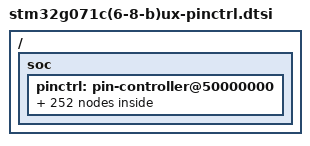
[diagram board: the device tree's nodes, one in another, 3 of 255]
/*
 * NOTE: Autogenerated file using genpinctrl.py
 *
 * SPDX-License-Identifier: Apache-2.0
 */

#include <zephyr/dt-bindings/pinctrl/stm32-pinctrl.h>

/ {
	soc {
		pinctrl: pin-controller@50000000 {

			/* ADC_IN / ADC_INN / ADC_INP */

			/omit-if-no-ref/ adc1_in0_pa0: adc1_in0_pa0 {
				pinmux = <STM32_PINMUX('A', 0, ANALOG)>;
			};

			/omit-if-no-ref/ adc1_in1_pa1: adc1_in1_pa1 {
				pinmux = <STM32_PINMUX('A', 1, ANALOG)>;
			};

			/omit-if-no-ref/ adc1_in2_pa2: adc1_in2_pa2 {
				pinmux = <STM32_PINMUX('A', 2, ANALOG)>;
			};

			/omit-if-no-ref/ adc1_in3_pa3: adc1_in3_pa3 {
				pinmux = <STM32_PINMUX('A', 3, ANALOG)>;
			};

			/omit-if-no-ref/ adc1_in4_pa4: adc1_in4_pa4 {
				pinmux = <STM32_PINMUX('A', 4, ANALOG)>;
			};

			/omit-if-no-ref/ adc1_in5_pa5: adc1_in5_pa5 {
				pinmux = <STM32_PINMUX('A', 5, ANALOG)>;
			};

			/omit-if-no-ref/ adc1_in6_pa6: adc1_in6_pa6 {
				pinmux = <STM32_PINMUX('A', 6, ANALOG)>;
			};

			/omit-if-no-ref/ adc1_in7_pa7: adc1_in7_pa7 {
				pinmux = <STM32_PINMUX('A', 7, ANALOG)>;
			};

			/omit-if-no-ref/ adc1_in8_pb0: adc1_in8_pb0 {
				pinmux = <STM32_PINMUX('B', 0, ANALOG)>;
			};

			/omit-if-no-ref/ adc1_in9_pb1: adc1_in9_pb1 {
				pinmux = <STM32_PINMUX('B', 1, ANALOG)>;
			};

			/omit-if-no-ref/ adc1_in10_pb2: adc1_in10_pb2 {
				pinmux = <STM32_PINMUX('B', 2, ANALOG)>;
			};

			/omit-if-no-ref/ adc1_in11_pb10: adc1_in11_pb10 {
				pinmux = <STM32_PINMUX('B', 10, ANALOG)>;
			};

			/omit-if-no-ref/ adc1_in15_pb11: adc1_in15_pb11 {
				pinmux = <STM32_PINMUX('B', 11, ANALOG)>;
			};

			/omit-if-no-ref/ adc1_in16_pb12: adc1_in16_pb12 {
				pinmux = <STM32_PINMUX('B', 12, ANALOG)>;
			};

			/* Analog */

			/omit-if-no-ref/ analog_pa0: analog_pa0 {
				pinmux = <STM32_PINMUX('A', 0, ANALOG)>;
			};

			/omit-if-no-ref/ analog_pa1: analog_pa1 {
				pinmux = <STM32_PINMUX('A', 1, ANALOG)>;
			};

			/omit-if-no-ref/ analog_pa2: analog_pa2 {
				pinmux = <STM32_PINMUX('A', 2, ANALOG)>;
			};

			/omit-if-no-ref/ analog_pa3: analog_pa3 {
				pinmux = <STM32_PINMUX('A', 3, ANALOG)>;
			};

			/omit-if-no-ref/ analog_pa4: analog_pa4 {
				pinmux = <STM32_PINMUX('A', 4, ANALOG)>;
			};

			/omit-if-no-ref/ analog_pa5: analog_pa5 {
				pinmux = <STM32_PINMUX('A', 5, ANALOG)>;
			};

			/omit-if-no-ref/ analog_pa6: analog_pa6 {
				pinmux = <STM32_PINMUX('A', 6, ANALOG)>;
			};

			/omit-if-no-ref/ analog_pa7: analog_pa7 {
				pinmux = <STM32_PINMUX('A', 7, ANALOG)>;
			};

			/omit-if-no-ref/ analog_pa8: analog_pa8 {
				pinmux = <STM32_PINMUX('A', 8, ANALOG)>;
			};

			/omit-if-no-ref/ analog_pa9: analog_pa9 {
				pinmux = <STM32_PINMUX('A', 9, ANALOG)>;
			};

			/omit-if-no-ref/ analog_pa10: analog_pa10 {
				pinmux = <STM32_PINMUX('A', 10, ANALOG)>;
			};

			/omit-if-no-ref/ analog_pa11: analog_pa11 {
				pinmux = <STM32_PINMUX('A', 11, ANALOG)>;
			};

			/omit-if-no-ref/ analog_pa12: analog_pa12 {
				pinmux = <STM32_PINMUX('A', 12, ANALOG)>;
			};

			/omit-if-no-ref/ analog_pa13: analog_pa13 {
				pinmux = <STM32_PINMUX('A', 13, ANALOG)>;
			};

			/omit-if-no-ref/ analog_pa14: analog_pa14 {
				pinmux = <STM32_PINMUX('A', 14, ANALOG)>;
			};

			/omit-if-no-ref/ analog_pa15: analog_pa15 {
				pinmux = <STM32_PINMUX('A', 15, ANALOG)>;
			};

			/omit-if-no-ref/ analog_pb0: analog_pb0 {
				pinmux = <STM32_PINMUX('B', 0, ANALOG)>;
			};

			/omit-if-no-ref/ analog_pb1: analog_pb1 {
				pinmux = <STM32_PINMUX('B', 1, ANALOG)>;
			};

			/omit-if-no-ref/ analog_pb2: analog_pb2 {
				pinmux = <STM32_PINMUX('B', 2, ANALOG)>;
			};

			/omit-if-no-ref/ analog_pb3: analog_pb3 {
				pinmux = <STM32_PINMUX('B', 3, ANALOG)>;
			};

			/omit-if-no-ref/ analog_pb4: analog_pb4 {
				pinmux = <STM32_PINMUX('B', 4, ANALOG)>;
			};

			/omit-if-no-ref/ analog_pb5: analog_pb5 {
				pinmux = <STM32_PINMUX('B', 5, ANALOG)>;
			};

			/omit-if-no-ref/ analog_pb6: analog_pb6 {
				pinmux = <STM32_PINMUX('B', 6, ANALOG)>;
			};

			/omit-if-no-ref/ analog_pb7: analog_pb7 {
				pinmux = <STM32_PINMUX('B', 7, ANALOG)>;
			};

			/omit-if-no-ref/ analog_pb8: analog_pb8 {
				pinmux = <STM32_PINMUX('B', 8, ANALOG)>;
			};

			/omit-if-no-ref/ analog_pb9: analog_pb9 {
				pinmux = <STM32_PINMUX('B', 9, ANALOG)>;
			};

			/omit-if-no-ref/ analog_pb10: analog_pb10 {
				pinmux = <STM32_PINMUX('B', 10, ANALOG)>;
			};

			/omit-if-no-ref/ analog_pb11: analog_pb11 {
				pinmux = <STM32_PINMUX('B', 11, ANALOG)>;
			};

			/omit-if-no-ref/ analog_pb12: analog_pb12 {
				pinmux = <STM32_PINMUX('B', 12, ANALOG)>;
			};

			/omit-if-no-ref/ analog_pb13: analog_pb13 {
				pinmux = <STM32_PINMUX('B', 13, ANALOG)>;
			};

			/omit-if-no-ref/ analog_pb14: analog_pb14 {
				pinmux = <STM32_PINMUX('B', 14, ANALOG)>;
			};

			/omit-if-no-ref/ analog_pb15: analog_pb15 {
				pinmux = <STM32_PINMUX('B', 15, ANALOG)>;
			};

			/omit-if-no-ref/ analog_pc6: analog_pc6 {
				pinmux = <STM32_PINMUX('C', 6, ANALOG)>;
			};

			/omit-if-no-ref/ analog_pc7: analog_pc7 {
				pinmux = <STM32_PINMUX('C', 7, ANALOG)>;
			};

			/omit-if-no-ref/ analog_pc13: analog_pc13 {
				pinmux = <STM32_PINMUX('C', 13, ANALOG)>;
			};

			/omit-if-no-ref/ analog_pc14: analog_pc14 {
				pinmux = <STM32_PINMUX('C', 14, ANALOG)>;
			};

			/omit-if-no-ref/ analog_pc15: analog_pc15 {
				pinmux = <STM32_PINMUX('C', 15, ANALOG)>;
			};

			/omit-if-no-ref/ analog_pd0: analog_pd0 {
				pinmux = <STM32_PINMUX('D', 0, ANALOG)>;
			};

			/omit-if-no-ref/ analog_pd1: analog_pd1 {
				pinmux = <STM32_PINMUX('D', 1, ANALOG)>;
			};

			/omit-if-no-ref/ analog_pd2: analog_pd2 {
				pinmux = <STM32_PINMUX('D', 2, ANALOG)>;
			};

			/omit-if-no-ref/ analog_pd3: analog_pd3 {
				pinmux = <STM32_PINMUX('D', 3, ANALOG)>;
			};

			/omit-if-no-ref/ analog_pf0: analog_pf0 {
				pinmux = <STM32_PINMUX('F', 0, ANALOG)>;
			};

			/omit-if-no-ref/ analog_pf1: analog_pf1 {
				pinmux = <STM32_PINMUX('F', 1, ANALOG)>;
			};

			/omit-if-no-ref/ analog_pf2: analog_pf2 {
				pinmux = <STM32_PINMUX('F', 2, ANALOG)>;
			};

			/* COMP_IN */

			/omit-if-no-ref/ comp1_inm_pa0: comp1_inm_pa0 {
				pinmux = <STM32_PINMUX('A', 0, ANALOG)>;
			};

			/omit-if-no-ref/ comp1_inp_pa1: comp1_inp_pa1 {
				pinmux = <STM32_PINMUX('A', 1, ANALOG)>;
			};

			/omit-if-no-ref/ comp1_inm_pb1: comp1_inm_pb1 {
				pinmux = <STM32_PINMUX('B', 1, ANALOG)>;
			};

			/omit-if-no-ref/ comp1_inp_pb2: comp1_inp_pb2 {
				pinmux = <STM32_PINMUX('B', 2, ANALOG)>;
			};

			/omit-if-no-ref/ comp2_inm_pa2: comp2_inm_pa2 {
				pinmux = <STM32_PINMUX('A', 2, ANALOG)>;
			};

			/omit-if-no-ref/ comp2_inp_pa3: comp2_inp_pa3 {
				pinmux = <STM32_PINMUX('A', 3, ANALOG)>;
			};

			/omit-if-no-ref/ comp2_inm_pb3: comp2_inm_pb3 {
				pinmux = <STM32_PINMUX('B', 3, ANALOG)>;
			};

			/omit-if-no-ref/ comp2_inp_pb4: comp2_inp_pb4 {
				pinmux = <STM32_PINMUX('B', 4, ANALOG)>;
			};

			/omit-if-no-ref/ comp2_inp_pb6: comp2_inp_pb6 {
				pinmux = <STM32_PINMUX('B', 6, ANALOG)>;
			};

			/omit-if-no-ref/ comp2_inm_pb7: comp2_inm_pb7 {
				pinmux = <STM32_PINMUX('B', 7, ANALOG)>;
			};

			/* COMP_OUT */

			/omit-if-no-ref/ comp1_out_pa0: comp1_out_pa0 {
				pinmux = <STM32_PINMUX('A', 0, AF7)>;
			};

			/omit-if-no-ref/ comp1_out_pa6: comp1_out_pa6 {
				pinmux = <STM32_PINMUX('A', 6, AF7)>;
			};

			/omit-if-no-ref/ comp1_out_pa11: comp1_out_pa11 {
				pinmux = <STM32_PINMUX('A', 11, AF7)>;
			};

			/omit-if-no-ref/ comp1_out_pb0: comp1_out_pb0 {
				pinmux = <STM32_PINMUX('B', 0, AF7)>;
			};

			/omit-if-no-ref/ comp1_out_pb10: comp1_out_pb10 {
				pinmux = <STM32_PINMUX('B', 10, AF7)>;
			};

			/omit-if-no-ref/ comp2_out_pa2: comp2_out_pa2 {
				pinmux = <STM32_PINMUX('A', 2, AF7)>;
			};

			/omit-if-no-ref/ comp2_out_pa7: comp2_out_pa7 {
				pinmux = <STM32_PINMUX('A', 7, AF7)>;
			};

			/omit-if-no-ref/ comp2_out_pa12: comp2_out_pa12 {
				pinmux = <STM32_PINMUX('A', 12, AF7)>;
			};

			/omit-if-no-ref/ comp2_out_pb5: comp2_out_pb5 {
				pinmux = <STM32_PINMUX('B', 5, AF7)>;
			};

			/omit-if-no-ref/ comp2_out_pb11: comp2_out_pb11 {
				pinmux = <STM32_PINMUX('B', 11, AF7)>;
			};

			/* DAC_OUT */

			/omit-if-no-ref/ dac1_out1_pa4: dac1_out1_pa4 {
				pinmux = <STM32_PINMUX('A', 4, ANALOG)>;
			};

			/omit-if-no-ref/ dac1_out2_pa5: dac1_out2_pa5 {
				pinmux = <STM32_PINMUX('A', 5, ANALOG)>;
			};

			/* I2C_SCL */

			/omit-if-no-ref/ i2c1_scl_pa9: i2c1_scl_pa9 {
				pinmux = <STM32_PINMUX('A', 9, AF6)>;
				bias-pull-up;
				drive-open-drain;
			};

			/omit-if-no-ref/ i2c1_scl_pb6: i2c1_scl_pb6 {
				pinmux = <STM32_PINMUX('B', 6, AF6)>;
				bias-pull-up;
				drive-open-drain;
			};

			/omit-if-no-ref/ i2c1_scl_pb8: i2c1_scl_pb8 {
				pinmux = <STM32_PINMUX('B', 8, AF6)>;
				bias-pull-up;
				drive-open-drain;
			};

			/omit-if-no-ref/ i2c2_scl_pa11: i2c2_scl_pa11 {
				pinmux = <STM32_PINMUX('A', 11, AF6)>;
				bias-pull-up;
				drive-open-drain;
			};

			/omit-if-no-ref/ i2c2_scl_pb10: i2c2_scl_pb10 {
				pinmux = <STM32_PINMUX('B', 10, AF6)>;
				bias-pull-up;
				drive-open-drain;
			};

			/omit-if-no-ref/ i2c2_scl_pb13: i2c2_scl_pb13 {
				pinmux = <STM32_PINMUX('B', 13, AF6)>;
				bias-pull-up;
				drive-open-drain;
			};

			/* I2C_SDA */

			/omit-if-no-ref/ i2c1_sda_pa10: i2c1_sda_pa10 {
				pinmux = <STM32_PINMUX('A', 10, AF6)>;
				bias-pull-up;
				drive-open-drain;
			};

			/omit-if-no-ref/ i2c1_sda_pb7: i2c1_sda_pb7 {
				pinmux = <STM32_PINMUX('B', 7, AF6)>;
				bias-pull-up;
				drive-open-drain;
			};

			/omit-if-no-ref/ i2c1_sda_pb9: i2c1_sda_pb9 {
				pinmux = <STM32_PINMUX('B', 9, AF6)>;
				bias-pull-up;
				drive-open-drain;
			};

			/omit-if-no-ref/ i2c2_sda_pa12: i2c2_sda_pa12 {
				pinmux = <STM32_PINMUX('A', 12, AF6)>;
				bias-pull-up;
				drive-open-drain;
			};

			/omit-if-no-ref/ i2c2_sda_pb11: i2c2_sda_pb11 {
				pinmux = <STM32_PINMUX('B', 11, AF6)>;
				bias-pull-up;
				drive-open-drain;
			};

			/omit-if-no-ref/ i2c2_sda_pb14: i2c2_sda_pb14 {
				pinmux = <STM32_PINMUX('B', 14, AF6)>;
				bias-pull-up;
				drive-open-drain;
			};

			/* I2C_SMBA */

			/omit-if-no-ref/ i2c1_smba_pa1: i2c1_smba_pa1 {
				pinmux = <STM32_PINMUX('A', 1, AF6)>;
				bias-pull-up;
			};

			/omit-if-no-ref/ i2c1_smba_pb5: i2c1_smba_pb5 {
				pinmux = <STM32_PINMUX('B', 5, AF6)>;
				bias-pull-up;
			};

			/* I2S_CK */

			/omit-if-no-ref/ i2s1_ck_pa1: i2s1_ck_pa1 {
				pinmux = <STM32_PINMUX('A', 1, AF0)>;
				slew-rate = "very-high-speed";
			};

			/omit-if-no-ref/ i2s1_ck_pa5: i2s1_ck_pa5 {
				pinmux = <STM32_PINMUX('A', 5, AF0)>;
				slew-rate = "very-high-speed";
			};

			/omit-if-no-ref/ i2s1_ck_pb3: i2s1_ck_pb3 {
				pinmux = <STM32_PINMUX('B', 3, AF0)>;
				slew-rate = "very-high-speed";
			};

			/* I2S_MCK */

			/omit-if-no-ref/ i2s1_mck_pa6: i2s1_mck_pa6 {
				pinmux = <STM32_PINMUX('A', 6, AF0)>;
				slew-rate = "very-high-speed";
			};

			/omit-if-no-ref/ i2s1_mck_pa11: i2s1_mck_pa11 {
				pinmux = <STM32_PINMUX('A', 11, AF0)>;
				slew-rate = "very-high-speed";
			};

			/omit-if-no-ref/ i2s1_mck_pb4: i2s1_mck_pb4 {
				pinmux = <STM32_PINMUX('B', 4, AF0)>;
				slew-rate = "very-high-speed";
			};

			/* I2S_SD */

			/omit-if-no-ref/ i2s1_sd_pa2: i2s1_sd_pa2 {
				pinmux = <STM32_PINMUX('A', 2, AF0)>;
			};

			/omit-if-no-ref/ i2s1_sd_pa7: i2s1_sd_pa7 {
				pinmux = <STM32_PINMUX('A', 7, AF0)>;
			};

			/omit-if-no-ref/ i2s1_sd_pa12: i2s1_sd_pa12 {
				pinmux = <STM32_PINMUX('A', 12, AF0)>;
			};

			/omit-if-no-ref/ i2s1_sd_pb5: i2s1_sd_pb5 {
				pinmux = <STM32_PINMUX('B', 5, AF0)>;
			};

			/* I2S_WS */

			/omit-if-no-ref/ i2s1_ws_pa4: i2s1_ws_pa4 {
				pinmux = <STM32_PINMUX('A', 4, AF0)>;
			};

			/omit-if-no-ref/ i2s1_ws_pa15: i2s1_ws_pa15 {
				pinmux = <STM32_PINMUX('A', 15, AF0)>;
			};

			/omit-if-no-ref/ i2s1_ws_pb0: i2s1_ws_pb0 {
				pinmux = <STM32_PINMUX('B', 0, AF0)>;
			};

			/* JTAG PORT */

			/omit-if-no-ref/ sys_swdio_pa13: sys_swdio_pa13 {
				pinmux = <STM32_PINMUX('A', 13, AF0)>;
			};

			/omit-if-no-ref/ sys_swclk_pa14: sys_swclk_pa14 {
				pinmux = <STM32_PINMUX('A', 14, AF0)>;
			};

			/* RCC_MCO */

			/omit-if-no-ref/ rcc_mco_pa8: rcc_mco_pa8 {
				pinmux = <STM32_PINMUX('A', 8, AF0)>;
				slew-rate = "very-high-speed";
			};

			/omit-if-no-ref/ rcc_mco_pa9: rcc_mco_pa9 {
				pinmux = <STM32_PINMUX('A', 9, AF0)>;
				slew-rate = "very-high-speed";
			};

			/omit-if-no-ref/ rcc_mco_pf2: rcc_mco_pf2 {
				pinmux = <STM32_PINMUX('F', 2, AF0)>;
				slew-rate = "very-high-speed";
			};

			/* SPI_MISO */

			/omit-if-no-ref/ spi1_miso_pa6: spi1_miso_pa6 {
				pinmux = <STM32_PINMUX('A', 6, AF0)>;
				bias-pull-down;
			};

			/omit-if-no-ref/ spi1_miso_pa11: spi1_miso_pa11 {
				pinmux = <STM32_PINMUX('A', 11, AF0)>;
				bias-pull-down;
			};

			/omit-if-no-ref/ spi1_miso_pb4: spi1_miso_pb4 {
				pinmux = <STM32_PINMUX('B', 4, AF0)>;
				bias-pull-down;
			};

			/omit-if-no-ref/ spi2_miso_pa3: spi2_miso_pa3 {
				pinmux = <STM32_PINMUX('A', 3, AF0)>;
				bias-pull-down;
			};

			/omit-if-no-ref/ spi2_miso_pa9: spi2_miso_pa9 {
				pinmux = <STM32_PINMUX('A', 9, AF4)>;
				bias-pull-down;
			};

			/omit-if-no-ref/ spi2_miso_pb2: spi2_miso_pb2 {
				pinmux = <STM32_PINMUX('B', 2, AF1)>;
				bias-pull-down;
			};

			/omit-if-no-ref/ spi2_miso_pb6: spi2_miso_pb6 {
				pinmux = <STM32_PINMUX('B', 6, AF4)>;
				bias-pull-down;
			};

			/omit-if-no-ref/ spi2_miso_pb14: spi2_miso_pb14 {
				pinmux = <STM32_PINMUX('B', 14, AF0)>;
				bias-pull-down;
			};

			/omit-if-no-ref/ spi2_miso_pd3: spi2_miso_pd3 {
				pinmux = <STM32_PINMUX('D', 3, AF1)>;
				bias-pull-down;
			};

			/* SPI_MOSI */

			/omit-if-no-ref/ spi1_mosi_pa2: spi1_mosi_pa2 {
				pinmux = <STM32_PINMUX('A', 2, AF0)>;
				bias-pull-down;
			};

			/omit-if-no-ref/ spi1_mosi_pa7: spi1_mosi_pa7 {
				pinmux = <STM32_PINMUX('A', 7, AF0)>;
				bias-pull-down;
			};

			/omit-if-no-ref/ spi1_mosi_pa12: spi1_mosi_pa12 {
				pinmux = <STM32_PINMUX('A', 12, AF0)>;
				bias-pull-down;
			};

			/omit-if-no-ref/ spi1_mosi_pb5: spi1_mosi_pb5 {
				pinmux = <STM32_PINMUX('B', 5, AF0)>;
				bias-pull-down;
			};

			/omit-if-no-ref/ spi2_mosi_pa4: spi2_mosi_pa4 {
				pinmux = <STM32_PINMUX('A', 4, AF1)>;
				bias-pull-down;
			};

			/omit-if-no-ref/ spi2_mosi_pa10: spi2_mosi_pa10 {
				pinmux = <STM32_PINMUX('A', 10, AF0)>;
				bias-pull-down;
			};

			/omit-if-no-ref/ spi2_mosi_pb7: spi2_mosi_pb7 {
				pinmux = <STM32_PINMUX('B', 7, AF1)>;
				bias-pull-down;
			};

			/omit-if-no-ref/ spi2_mosi_pb11: spi2_mosi_pb11 {
				pinmux = <STM32_PINMUX('B', 11, AF0)>;
				bias-pull-down;
			};

			/omit-if-no-ref/ spi2_mosi_pb15: spi2_mosi_pb15 {
				pinmux = <STM32_PINMUX('B', 15, AF0)>;
				bias-pull-down;
			};

			/* SPI_NSS */

			/omit-if-no-ref/ spi1_nss_pa4: spi1_nss_pa4 {
				pinmux = <STM32_PINMUX('A', 4, AF0)>;
				bias-pull-up;
			};

			/omit-if-no-ref/ spi1_nss_pa15: spi1_nss_pa15 {
				pinmux = <STM32_PINMUX('A', 15, AF0)>;
				bias-pull-up;
			};

			/omit-if-no-ref/ spi1_nss_pb0: spi1_nss_pb0 {
				pinmux = <STM32_PINMUX('B', 0, AF0)>;
				bias-pull-up;
			};

			/omit-if-no-ref/ spi2_nss_pa8: spi2_nss_pa8 {
				pinmux = <STM32_PINMUX('A', 8, AF1)>;
				bias-pull-up;
			};

			/omit-if-no-ref/ spi2_nss_pb9: spi2_nss_pb9 {
				pinmux = <STM32_PINMUX('B', 9, AF5)>;
				bias-pull-up;
			};

			/omit-if-no-ref/ spi2_nss_pb12: spi2_nss_pb12 {
				pinmux = <STM32_PINMUX('B', 12, AF0)>;
				bias-pull-up;
			};

			/omit-if-no-ref/ spi2_nss_pd0: spi2_nss_pd0 {
				pinmux = <STM32_PINMUX('D', 0, AF1)>;
				bias-pull-up;
			};

			/* SPI_SCK */

			/omit-if-no-ref/ spi1_sck_pa1: spi1_sck_pa1 {
				pinmux = <STM32_PINMUX('A', 1, AF0)>;
				bias-pull-down;
				slew-rate = "very-high-speed";
			};

			/omit-if-no-ref/ spi1_sck_pa5: spi1_sck_pa5 {
				pinmux = <STM32_PINMUX('A', 5, AF0)>;
				bias-pull-down;
				slew-rate = "very-high-speed";
			};

			/omit-if-no-ref/ spi1_sck_pb3: spi1_sck_pb3 {
				pinmux = <STM32_PINMUX('B', 3, AF0)>;
				bias-pull-down;
				slew-rate = "very-high-speed";
			};

			/omit-if-no-ref/ spi2_sck_pa0: spi2_sck_pa0 {
				pinmux = <STM32_PINMUX('A', 0, AF0)>;
				bias-pull-down;
				slew-rate = "very-high-speed";
			};

			/omit-if-no-ref/ spi2_sck_pb8: spi2_sck_pb8 {
				pinmux = <STM32_PINMUX('B', 8, AF1)>;
				bias-pull-down;
				slew-rate = "very-high-speed";
			};

			/omit-if-no-ref/ spi2_sck_pb10: spi2_sck_pb10 {
				pinmux = <STM32_PINMUX('B', 10, AF5)>;
				bias-pull-down;
				slew-rate = "very-high-speed";
			};

			/omit-if-no-ref/ spi2_sck_pb13: spi2_sck_pb13 {
				pinmux = <STM32_PINMUX('B', 13, AF0)>;
				bias-pull-down;
				slew-rate = "very-high-speed";
			};

			/omit-if-no-ref/ spi2_sck_pd1: spi2_sck_pd1 {
				pinmux = <STM32_PINMUX('D', 1, AF1)>;
				bias-pull-down;
				slew-rate = "very-high-speed";
			};

			/* TIM_CH / TIM_CHN */

			/omit-if-no-ref/ tim1_ch1n_pa7: tim1_ch1n_pa7 {
				pinmux = <STM32_PINMUX('A', 7, AF2)>;
			};

			/omit-if-no-ref/ tim1_ch1_pa8: tim1_ch1_pa8 {
				pinmux = <STM32_PINMUX('A', 8, AF2)>;
			};

			/omit-if-no-ref/ tim1_ch2_pa9: tim1_ch2_pa9 {
				pinmux = <STM32_PINMUX('A', 9, AF2)>;
			};

			/omit-if-no-ref/ tim1_ch3_pa10: tim1_ch3_pa10 {
				pinmux = <STM32_PINMUX('A', 10, AF2)>;
			};

			/omit-if-no-ref/ tim1_ch4_pa11: tim1_ch4_pa11 {
				pinmux = <STM32_PINMUX('A', 11, AF2)>;
			};

			/omit-if-no-ref/ tim1_ch2n_pb0: tim1_ch2n_pb0 {
				pinmux = <STM32_PINMUX('B', 0, AF2)>;
			};

			/omit-if-no-ref/ tim1_ch3n_pb1: tim1_ch3n_pb1 {
				pinmux = <STM32_PINMUX('B', 1, AF2)>;
			};

			/omit-if-no-ref/ tim1_ch2_pb3: tim1_ch2_pb3 {
				pinmux = <STM32_PINMUX('B', 3, AF1)>;
			};

			/omit-if-no-ref/ tim1_ch3_pb6: tim1_ch3_pb6 {
				pinmux = <STM32_PINMUX('B', 6, AF1)>;
			};

			/omit-if-no-ref/ tim1_ch1n_pb13: tim1_ch1n_pb13 {
				pinmux = <STM32_PINMUX('B', 13, AF2)>;
			};

			/omit-if-no-ref/ tim1_ch2n_pb14: tim1_ch2n_pb14 {
				pinmux = <STM32_PINMUX('B', 14, AF2)>;
			};

			/omit-if-no-ref/ tim1_ch3n_pb15: tim1_ch3n_pb15 {
				pinmux = <STM32_PINMUX('B', 15, AF2)>;
			};

			/omit-if-no-ref/ tim1_ch1n_pd2: tim1_ch1n_pd2 {
				pinmux = <STM32_PINMUX('D', 2, AF2)>;
			};

			/omit-if-no-ref/ tim1_ch2n_pd3: tim1_ch2n_pd3 {
				pinmux = <STM32_PINMUX('D', 3, AF2)>;
			};

			/omit-if-no-ref/ tim2_ch1_pa0: tim2_ch1_pa0 {
				pinmux = <STM32_PINMUX('A', 0, AF2)>;
			};

			/omit-if-no-ref/ tim2_ch2_pa1: tim2_ch2_pa1 {
				pinmux = <STM32_PINMUX('A', 1, AF2)>;
			};

			/omit-if-no-ref/ tim2_ch3_pa2: tim2_ch3_pa2 {
				pinmux = <STM32_PINMUX('A', 2, AF2)>;
			};

			/omit-if-no-ref/ tim2_ch4_pa3: tim2_ch4_pa3 {
				pinmux = <STM32_PINMUX('A', 3, AF2)>;
			};

			/omit-if-no-ref/ tim2_ch1_pa5: tim2_ch1_pa5 {
				pinmux = <STM32_PINMUX('A', 5, AF2)>;
			};

			/omit-if-no-ref/ tim2_ch1_pa15: tim2_ch1_pa15 {
				pinmux = <STM32_PINMUX('A', 15, AF2)>;
			};

			/omit-if-no-ref/ tim2_ch2_pb3: tim2_ch2_pb3 {
				pinmux = <STM32_PINMUX('B', 3, AF2)>;
			};

			/omit-if-no-ref/ tim2_ch3_pb10: tim2_ch3_pb10 {
				pinmux = <STM32_PINMUX('B', 10, AF2)>;
			};

			/omit-if-no-ref/ tim2_ch4_pb11: tim2_ch4_pb11 {
				pinmux = <STM32_PINMUX('B', 11, AF2)>;
			};

			/omit-if-no-ref/ tim2_ch3_pc6: tim2_ch3_pc6 {
				pinmux = <STM32_PINMUX('C', 6, AF2)>;
			};

			/omit-if-no-ref/ tim2_ch4_pc7: tim2_ch4_pc7 {
				pinmux = <STM32_PINMUX('C', 7, AF2)>;
			};

			/omit-if-no-ref/ tim3_ch1_pa6: tim3_ch1_pa6 {
				pinmux = <STM32_PINMUX('A', 6, AF1)>;
			};

			/omit-if-no-ref/ tim3_ch2_pa7: tim3_ch2_pa7 {
				pinmux = <STM32_PINMUX('A', 7, AF1)>;
			};

			/omit-if-no-ref/ tim3_ch3_pb0: tim3_ch3_pb0 {
				pinmux = <STM32_PINMUX('B', 0, AF1)>;
			};

			/omit-if-no-ref/ tim3_ch4_pb1: tim3_ch4_pb1 {
				pinmux = <STM32_PINMUX('B', 1, AF1)>;
			};

			/omit-if-no-ref/ tim3_ch1_pb4: tim3_ch1_pb4 {
				pinmux = <STM32_PINMUX('B', 4, AF1)>;
			};

			/omit-if-no-ref/ tim3_ch2_pb5: tim3_ch2_pb5 {
				pinmux = <STM32_PINMUX('B', 5, AF1)>;
			};

			/omit-if-no-ref/ tim3_ch1_pc6: tim3_ch1_pc6 {
				pinmux = <STM32_PINMUX('C', 6, AF1)>;
			};

			/omit-if-no-ref/ tim3_ch2_pc7: tim3_ch2_pc7 {
				pinmux = <STM32_PINMUX('C', 7, AF1)>;
			};

			/omit-if-no-ref/ tim14_ch1_pa4: tim14_ch1_pa4 {
				pinmux = <STM32_PINMUX('A', 4, AF4)>;
			};

			/omit-if-no-ref/ tim14_ch1_pa7: tim14_ch1_pa7 {
				pinmux = <STM32_PINMUX('A', 7, AF4)>;
			};

			/omit-if-no-ref/ tim14_ch1_pb1: tim14_ch1_pb1 {
				pinmux = <STM32_PINMUX('B', 1, AF0)>;
			};

			/omit-if-no-ref/ tim14_ch1_pf0: tim14_ch1_pf0 {
				pinmux = <STM32_PINMUX('F', 0, AF2)>;
			};

			/omit-if-no-ref/ tim15_ch1n_pa1: tim15_ch1n_pa1 {
				pinmux = <STM32_PINMUX('A', 1, AF5)>;
			};

			/omit-if-no-ref/ tim15_ch1_pa2: tim15_ch1_pa2 {
				pinmux = <STM32_PINMUX('A', 2, AF5)>;
			};

			/omit-if-no-ref/ tim15_ch2_pa3: tim15_ch2_pa3 {
				pinmux = <STM32_PINMUX('A', 3, AF5)>;
			};

			/omit-if-no-ref/ tim15_ch1n_pb13: tim15_ch1n_pb13 {
				pinmux = <STM32_PINMUX('B', 13, AF5)>;
			};

			/omit-if-no-ref/ tim15_ch1_pb14: tim15_ch1_pb14 {
				pinmux = <STM32_PINMUX('B', 14, AF5)>;
			};

			/omit-if-no-ref/ tim15_ch1n_pb15: tim15_ch1n_pb15 {
				pinmux = <STM32_PINMUX('B', 15, AF4)>;
			};

			/omit-if-no-ref/ tim15_ch2_pb15: tim15_ch2_pb15 {
				pinmux = <STM32_PINMUX('B', 15, AF5)>;
			};

			/omit-if-no-ref/ tim15_ch1n_pf1: tim15_ch1n_pf1 {
				pinmux = <STM32_PINMUX('F', 1, AF2)>;
			};

			/omit-if-no-ref/ tim16_ch1_pa6: tim16_ch1_pa6 {
				pinmux = <STM32_PINMUX('A', 6, AF5)>;
			};

			/omit-if-no-ref/ tim16_ch1n_pb6: tim16_ch1n_pb6 {
				pinmux = <STM32_PINMUX('B', 6, AF2)>;
			};

			/omit-if-no-ref/ tim16_ch1_pb8: tim16_ch1_pb8 {
				pinmux = <STM32_PINMUX('B', 8, AF2)>;
			};

			/omit-if-no-ref/ tim16_ch1_pd0: tim16_ch1_pd0 {
				pinmux = <STM32_PINMUX('D', 0, AF2)>;
			};

			/omit-if-no-ref/ tim17_ch1_pa7: tim17_ch1_pa7 {
				pinmux = <STM32_PINMUX('A', 7, AF5)>;
			};

			/omit-if-no-ref/ tim17_ch1n_pb7: tim17_ch1n_pb7 {
				pinmux = <STM32_PINMUX('B', 7, AF2)>;
			};

			/omit-if-no-ref/ tim17_ch1_pb9: tim17_ch1_pb9 {
				pinmux = <STM32_PINMUX('B', 9, AF2)>;
			};

			/omit-if-no-ref/ tim17_ch1_pd1: tim17_ch1_pd1 {
				pinmux = <STM32_PINMUX('D', 1, AF2)>;
			};

			/* UART_CTS / USART_CTS / LPUART_CTS */

			/omit-if-no-ref/ lpuart1_cts_pa6: lpuart1_cts_pa6 {
				pinmux = <STM32_PINMUX('A', 6, AF6)>;
				bias-pull-up;
			};

			/omit-if-no-ref/ usart1_cts_pa11: usart1_cts_pa11 {
				pinmux = <STM32_PINMUX('A', 11, AF1)>;
				bias-pull-up;
			};

			/omit-if-no-ref/ usart1_cts_pb4: usart1_cts_pb4 {
				pinmux = <STM32_PINMUX('B', 4, AF4)>;
				bias-pull-up;
			};

			/omit-if-no-ref/ lpuart1_cts_pb13: lpuart1_cts_pb13 {
				pinmux = <STM32_PINMUX('B', 13, AF1)>;
				bias-pull-up;
			};

			/omit-if-no-ref/ usart2_cts_pa0: usart2_cts_pa0 {
				pinmux = <STM32_PINMUX('A', 0, AF1)>;
				bias-pull-up;
			};

			/omit-if-no-ref/ usart2_cts_pd3: usart2_cts_pd3 {
				pinmux = <STM32_PINMUX('D', 3, AF0)>;
				bias-pull-up;
			};

			/omit-if-no-ref/ usart3_cts_pa6: usart3_cts_pa6 {
				pinmux = <STM32_PINMUX('A', 6, AF4)>;
				bias-pull-up;
			};

			/omit-if-no-ref/ usart3_cts_pb13: usart3_cts_pb13 {
				pinmux = <STM32_PINMUX('B', 13, AF4)>;
				bias-pull-up;
			};

			/omit-if-no-ref/ usart4_cts_pb7: usart4_cts_pb7 {
				pinmux = <STM32_PINMUX('B', 7, AF4)>;
				bias-pull-up;
			};

			/* UART_DE / USART_DE / LPUART_DE */

			/omit-if-no-ref/ usart1_de_pa12: usart1_de_pa12 {
				pinmux = <STM32_PINMUX('A', 12, AF1)>;
				drive-push-pull;
			};

			/omit-if-no-ref/ lpuart1_de_pb1: lpuart1_de_pb1 {
				pinmux = <STM32_PINMUX('B', 1, AF6)>;
				drive-push-pull;
			};

			/omit-if-no-ref/ usart1_de_pb3: usart1_de_pb3 {
				pinmux = <STM32_PINMUX('B', 3, AF4)>;
				drive-push-pull;
			};

			/omit-if-no-ref/ lpuart1_de_pb12: lpuart1_de_pb12 {
				pinmux = <STM32_PINMUX('B', 12, AF1)>;
				drive-push-pull;
			};

			/omit-if-no-ref/ usart2_de_pa1: usart2_de_pa1 {
				pinmux = <STM32_PINMUX('A', 1, AF1)>;
				drive-push-pull;
			};

			/omit-if-no-ref/ usart3_de_pa15: usart3_de_pa15 {
				pinmux = <STM32_PINMUX('A', 15, AF5)>;
				drive-push-pull;
			};

			/omit-if-no-ref/ usart3_de_pb1: usart3_de_pb1 {
				pinmux = <STM32_PINMUX('B', 1, AF4)>;
				drive-push-pull;
			};

			/omit-if-no-ref/ usart3_de_pb14: usart3_de_pb14 {
				pinmux = <STM32_PINMUX('B', 14, AF4)>;
				drive-push-pull;
			};

			/omit-if-no-ref/ usart3_de_pd2: usart3_de_pd2 {
				pinmux = <STM32_PINMUX('D', 2, AF0)>;
				drive-push-pull;
			};

			/omit-if-no-ref/ usart4_de_pa15: usart4_de_pa15 {
				pinmux = <STM32_PINMUX('A', 15, AF4)>;
				drive-push-pull;
			};

			/* UART_RTS / USART_RTS / LPUART_RTS */

			/omit-if-no-ref/ usart1_rts_pa12: usart1_rts_pa12 {
				pinmux = <STM32_PINMUX('A', 12, AF1)>;
				drive-push-pull;
			};

			/omit-if-no-ref/ lpuart1_rts_pb1: lpuart1_rts_pb1 {
				pinmux = <STM32_PINMUX('B', 1, AF6)>;
				drive-push-pull;
			};

			/omit-if-no-ref/ usart1_rts_pb3: usart1_rts_pb3 {
				pinmux = <STM32_PINMUX('B', 3, AF4)>;
				drive-push-pull;
			};

			/omit-if-no-ref/ lpuart1_rts_pb12: lpuart1_rts_pb12 {
				pinmux = <STM32_PINMUX('B', 12, AF1)>;
				drive-push-pull;
			};

			/omit-if-no-ref/ usart2_rts_pa1: usart2_rts_pa1 {
				pinmux = <STM32_PINMUX('A', 1, AF1)>;
				drive-push-pull;
			};

			/omit-if-no-ref/ usart3_rts_pa15: usart3_rts_pa15 {
				pinmux = <STM32_PINMUX('A', 15, AF5)>;
				drive-push-pull;
			};

			/omit-if-no-ref/ usart3_rts_pb1: usart3_rts_pb1 {
				pinmux = <STM32_PINMUX('B', 1, AF4)>;
				drive-push-pull;
			};

			/omit-if-no-ref/ usart3_rts_pb14: usart3_rts_pb14 {
				pinmux = <STM32_PINMUX('B', 14, AF4)>;
				drive-push-pull;
			};

			/omit-if-no-ref/ usart3_rts_pd2: usart3_rts_pd2 {
				pinmux = <STM32_PINMUX('D', 2, AF0)>;
				drive-push-pull;
			};

			/omit-if-no-ref/ usart4_rts_pa15: usart4_rts_pa15 {
				pinmux = <STM32_PINMUX('A', 15, AF4)>;
				drive-push-pull;
			};

			/* UART_RX / USART_RX / LPUART_RX */

			/omit-if-no-ref/ lpuart1_rx_pa3: lpuart1_rx_pa3 {
				pinmux = <STM32_PINMUX('A', 3, AF6)>;
			};

			/omit-if-no-ref/ usart1_rx_pa10: usart1_rx_pa10 {
				pinmux = <STM32_PINMUX('A', 10, AF1)>;
			};

			/omit-if-no-ref/ usart1_rx_pb7: usart1_rx_pb7 {
				pinmux = <STM32_PINMUX('B', 7, AF0)>;
			};

			/omit-if-no-ref/ lpuart1_rx_pb10: lpuart1_rx_pb10 {
				pinmux = <STM32_PINMUX('B', 10, AF1)>;
			};

			/omit-if-no-ref/ usart2_rx_pa3: usart2_rx_pa3 {
				pinmux = <STM32_PINMUX('A', 3, AF1)>;
			};

			/omit-if-no-ref/ usart2_rx_pa15: usart2_rx_pa15 {
				pinmux = <STM32_PINMUX('A', 15, AF1)>;
			};

			/omit-if-no-ref/ usart3_rx_pb0: usart3_rx_pb0 {
				pinmux = <STM32_PINMUX('B', 0, AF4)>;
			};

			/omit-if-no-ref/ usart3_rx_pb9: usart3_rx_pb9 {
				pinmux = <STM32_PINMUX('B', 9, AF4)>;
			};

			/omit-if-no-ref/ usart3_rx_pb11: usart3_rx_pb11 {
				pinmux = <STM32_PINMUX('B', 11, AF4)>;
			};

			/omit-if-no-ref/ usart4_rx_pa1: usart4_rx_pa1 {
				pinmux = <STM32_PINMUX('A', 1, AF4)>;
			};

			/* UART_TX / USART_TX / LPUART_TX */

			/omit-if-no-ref/ lpuart1_tx_pa2: lpuart1_tx_pa2 {
				pinmux = <STM32_PINMUX('A', 2, AF6)>;
				bias-pull-up;
			};

			/omit-if-no-ref/ usart1_tx_pa9: usart1_tx_pa9 {
				pinmux = <STM32_PINMUX('A', 9, AF1)>;
				bias-pull-up;
			};

			/omit-if-no-ref/ usart1_tx_pb6: usart1_tx_pb6 {
				pinmux = <STM32_PINMUX('B', 6, AF0)>;
				bias-pull-up;
			};

			/omit-if-no-ref/ lpuart1_tx_pb11: lpuart1_tx_pb11 {
				pinmux = <STM32_PINMUX('B', 11, AF1)>;
				bias-pull-up;
			};

			/omit-if-no-ref/ usart2_tx_pa2: usart2_tx_pa2 {
				pinmux = <STM32_PINMUX('A', 2, AF1)>;
				bias-pull-up;
			};

			/omit-if-no-ref/ usart2_tx_pa14: usart2_tx_pa14 {
				pinmux = <STM32_PINMUX('A', 14, AF1)>;
				bias-pull-up;
			};

			/omit-if-no-ref/ usart3_tx_pa5: usart3_tx_pa5 {
				pinmux = <STM32_PINMUX('A', 5, AF4)>;
				bias-pull-up;
			};

			/omit-if-no-ref/ usart3_tx_pb2: usart3_tx_pb2 {
				pinmux = <STM32_PINMUX('B', 2, AF4)>;
				bias-pull-up;
			};

			/omit-if-no-ref/ usart3_tx_pb8: usart3_tx_pb8 {
				pinmux = <STM32_PINMUX('B', 8, AF4)>;
				bias-pull-up;
			};

			/omit-if-no-ref/ usart3_tx_pb10: usart3_tx_pb10 {
				pinmux = <STM32_PINMUX('B', 10, AF4)>;
				bias-pull-up;
			};

			/omit-if-no-ref/ usart4_tx_pa0: usart4_tx_pa0 {
				pinmux = <STM32_PINMUX('A', 0, AF4)>;
				bias-pull-up;
			};

			/* UCPD */

			/omit-if-no-ref/ ucpd1_cc1_pa8: ucpd1_cc1_pa8 {
				pinmux = <STM32_PINMUX('A', 8, ANALOG)>;
			};

			/omit-if-no-ref/ ucpd1_cc2_pb15: ucpd1_cc2_pb15 {
				pinmux = <STM32_PINMUX('B', 15, ANALOG)>;
			};

			/omit-if-no-ref/ ucpd2_cc1_pd0: ucpd2_cc1_pd0 {
				pinmux = <STM32_PINMUX('D', 0, ANALOG)>;
			};

			/omit-if-no-ref/ ucpd2_cc2_pd2: ucpd2_cc2_pd2 {
				pinmux = <STM32_PINMUX('D', 2, ANALOG)>;
			};

		};
	};
};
